# PIC32MM0032GPL020 device description
Architecture: MIPS; Family: PIC32MM1324; Series: PIC32MM
Registers are 32-bit, read-write, no defined reset value unless marked. A register's access mark holds for its fields unless they carry their own. Offsets are from the block's base; [hi:lo] are bit positions; {n}, {i} and the like mark numbered series; 'fields as' and 'values as' point back to an identical list.

## CMP
Instances: CMP 0x1f800900 in periph0
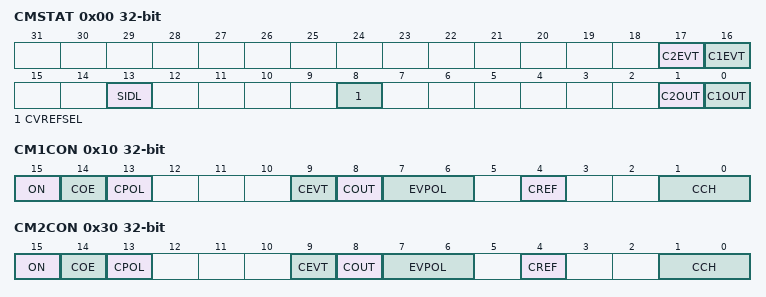
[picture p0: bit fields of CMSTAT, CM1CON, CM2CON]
0x00 CMSTAT
  [17] C2EVT
  [16] C1EVT
  [13] SIDL — Stop in Idle Control bit
    1=All Comparator modules are disabled in Idle mode; 0=All Comparator modules continue to operate in the Idle mode
  [8] CVREFSEL — Comparator Reference Voltage Select (CVREFSEL)
    1=External voltage reference from the CVREF+ pin is selected; 0=Internal band gap voltage reference is selected
  [1] C2OUT — Comparator 2 Output bit
    1=Output of Comparator 2 is a 1; 0=Output of Comparator 2 is a 0
  [0] C1OUT — Comparator 1 Output bit
    1=Output of Comparator 1 is a 1; 0=Output of Comparator 1 is a 0
0x10 CM1CON
  [15] ON — Comparator ON bit
    1=Module is enabled. Setting this bit does not affect the other bits in this register; 0=Module is disabled and does not consume current. Clearing this bit does not affect the other bits in this register
  [14] COE — Comparator Output Enable bit
    1=Comparator output is driven on the output CxOUT pin; 0=Comparator output is not driven on the output CxOUT pin
  [13] CPOL — Comparator Output Inversion bit
    1=Output is inverted; 0=Output is not inverted
  [9] CEVT
  [8] COUT — Comparator Output bit
    1=VIN+ is greater than VIN- (if CPOL = 0)/VIN+ is smaller than VIN- (if CPOL = 1); 0=VIN+ is greater than VIN- (if CPOL = 1)/VIN+ is smaller than VIN- (if CPOL = 0)
  [7:6] EVPOL — Interrupt Event Polarity Select bits
    3=Comparator event is generated on any change of the comparator output; 2=Comparator event is generated on a high-to-low transition (if CPOL = 0) or low-to-high transition (if CPOL = 1) of the comparator output; 1=Comparator event is generated on a high-to-low transition (if CPOL = 1) or low-to-high transition (if CPOL = 0) of the comparator output; 0=Comparator event generation is disabled
  [4] CREF — Comparator Positive Input Configuration
    1=Comparator Non-inverting input connects to the reference defined by the CVREFSEL bit; 0=Comparator non-inverting input is connected to the CxINA pin
  [1:0] CCH — Comparator Negative Input Configuration
    3=Comparator inverting input is connected to the band gap reference voltage; 2=Comparator inverting input is connected to the CxIND pin; 1=Comparator inverting input is connected to the CxINC pin; 0=Comparator inverting input is connected to the CxINB pin
0x30 CM2CON
  fields as CM1CON

## CRC
Instances: CRC 0x1f800a00 in periph0
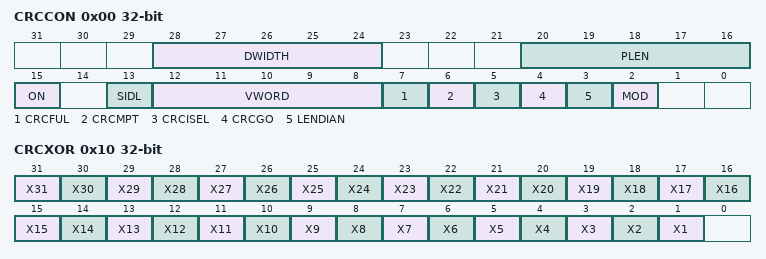
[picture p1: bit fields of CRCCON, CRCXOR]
0x00 CRCCON
  [28:24] DWIDTH, [20:16] PLEN, [15] ON, [13] SIDL, [12:8] VWORD, [7] CRCFUL, [6] CRCMPT, [5] CRCISEL, [4] CRCGO, [3] LENDIAN, [2] MOD
0x10 CRCXOR
  [n] X{n} (n=1..31)
0x20 CRCDAT wo
0x30 CRCWDAT

## GPIO
Instances: GPIO 0x1f802300 in periph0
0x180 RPCON
  [11] IOLOCK
0x1A0 RPINR1
  [4:0] INT4R
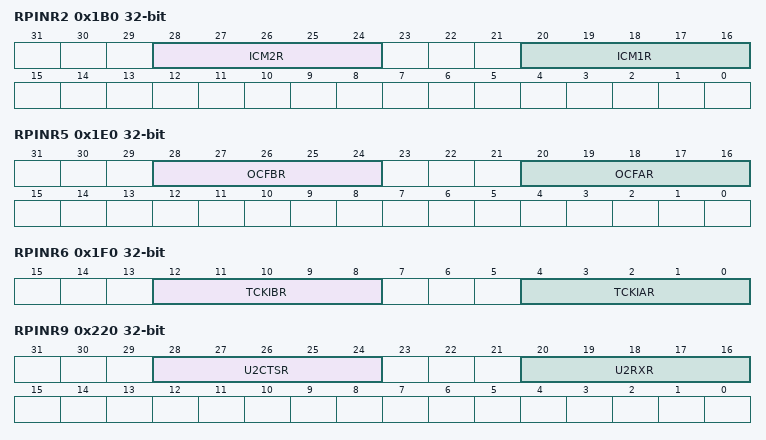
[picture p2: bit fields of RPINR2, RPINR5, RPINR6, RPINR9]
0x1B0 RPINR2
  [28:24] ICM2R, [20:16] ICM1R
0x1C0 RPINR3
  [4:0] ICM3R
0x1E0 RPINR5
  [28:24] OCFBR, [20:16] OCFAR
0x1F0 RPINR6
  [12:8] TCKIBR, [4:0] TCKIAR
0x220 RPINR9
  [28:24] U2CTSR, [20:16] U2RXR
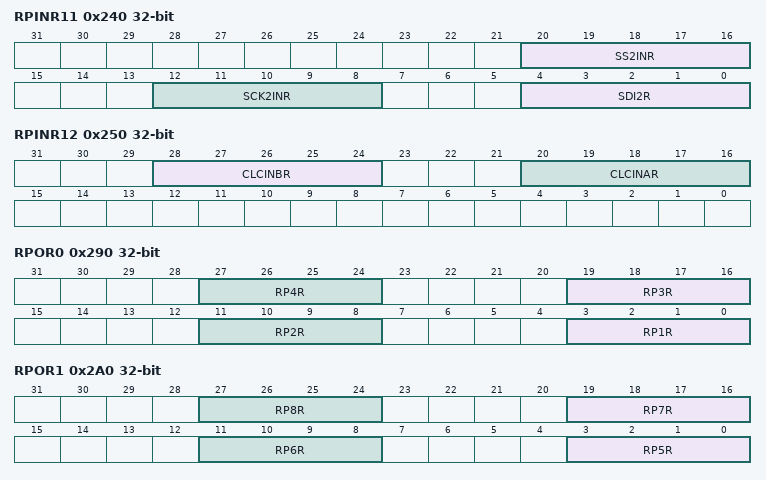
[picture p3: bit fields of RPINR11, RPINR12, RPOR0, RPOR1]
0x240 RPINR11
  [20:16] SS2INR, [12:8] SCK2INR, [4:0] SDI2R
0x250 RPINR12
  [28:24] CLCINBR, [20:16] CLCINAR
0x290 RPOR0
  [8n-5:8n-8] RP{n}R (n=1..4)
0x2A0 RPOR1
  [8n-37:8n-40] RP{n}R (n=5..8)
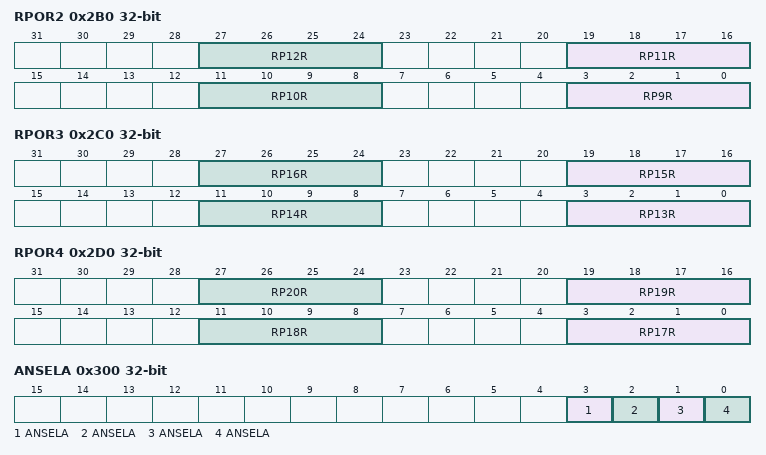
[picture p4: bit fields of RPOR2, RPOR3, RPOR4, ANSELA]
0x2B0 RPOR2
  [8n-69:8n-72] RP{n}R (n=9..12)
0x2C0 RPOR3
  [8n-101:8n-104] RP{n}R (n=13..16)
0x2D0 RPOR4
  [8n-133:8n-136] RP{n}R (n=17..20)
0x300 ANSELA
  [3] ANSELA, [2] ANSELA, [1] ANSELA, [0] ANSELA
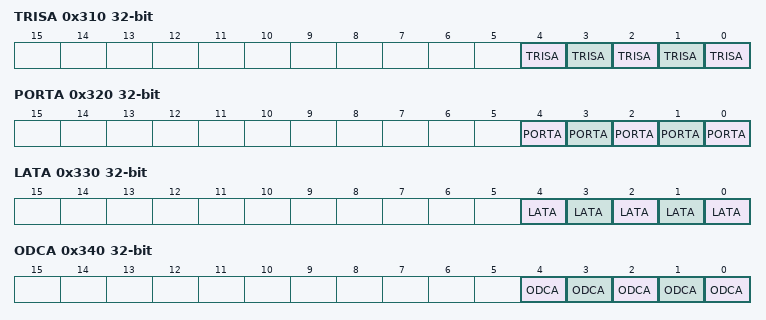
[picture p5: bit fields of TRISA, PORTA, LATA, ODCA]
0x310 TRISA
  [4] TRISA, [3] TRISA, [2] TRISA, [1] TRISA, [0] TRISA
0x320 PORTA
  [4] PORTA, [3] PORTA, [2] PORTA, [1] PORTA, [0] PORTA
0x330 LATA
  [4] LATA, [3] LATA, [2] LATA, [1] LATA, [0] LATA
0x340 ODCA
  [4] ODCA, [3] ODCA, [2] ODCA, [1] ODCA, [0] ODCA
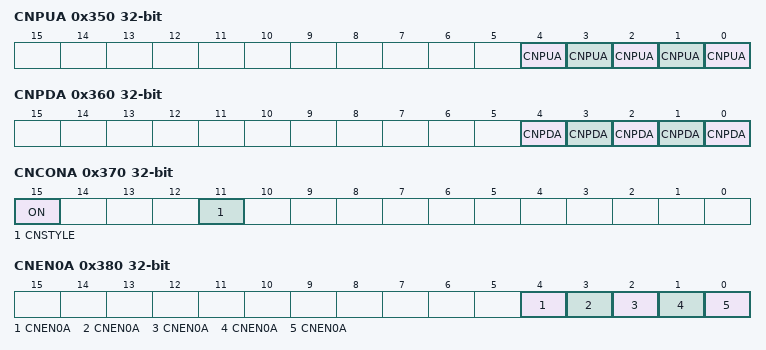
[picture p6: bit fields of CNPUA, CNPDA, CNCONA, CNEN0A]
0x350 CNPUA
  [4] CNPUA, [3] CNPUA, [2] CNPUA, [1] CNPUA, [0] CNPUA
0x360 CNPDA
  [4] CNPDA, [3] CNPDA, [2] CNPDA, [1] CNPDA, [0] CNPDA
0x370 CNCONA
  [15] ON, [11] CNSTYLE
0x380 CNEN0A
  [4] CNEN0A, [3] CNEN0A, [2] CNEN0A, [1] CNEN0A, [0] CNEN0A
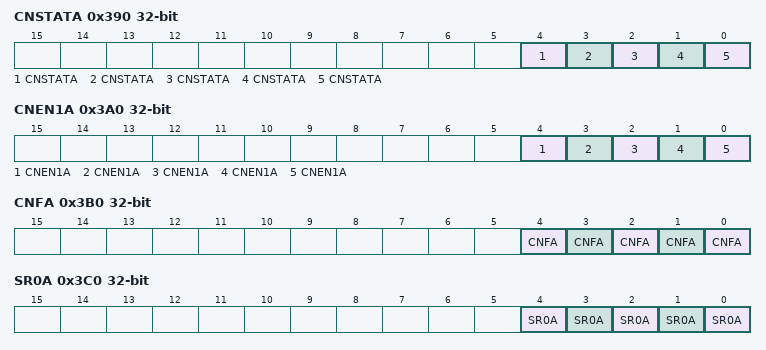
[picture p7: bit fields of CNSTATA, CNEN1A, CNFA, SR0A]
0x390 CNSTATA
  [4] CNSTATA, [3] CNSTATA, [2] CNSTATA, [1] CNSTATA, [0] CNSTATA
0x3A0 CNEN1A
  [4] CNEN1A, [3] CNEN1A, [2] CNEN1A, [1] CNEN1A, [0] CNEN1A
0x3B0 CNFA
  [4] CNFA, [3] CNFA, [2] CNFA, [1] CNFA, [0] CNFA
0x3C0 SR0A
  [4] SR0A, [3] SR0A, [2] SR0A, [1] SR0A, [0] SR0A
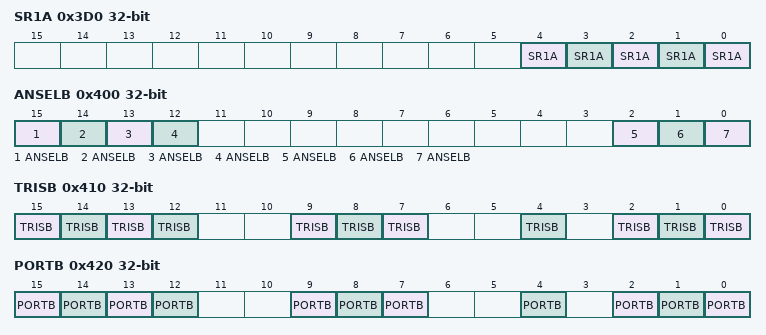
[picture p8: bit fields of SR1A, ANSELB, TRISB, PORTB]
0x3D0 SR1A
  [4] SR1A, [3] SR1A, [2] SR1A, [1] SR1A, [0] SR1A
0x400 ANSELB
  [15] ANSELB, [14] ANSELB, [13] ANSELB, [12] ANSELB, [2] ANSELB, [1] ANSELB, [0] ANSELB
0x410 TRISB
  [15] TRISB, [14] TRISB, [13] TRISB, [12] TRISB, [9] TRISB, [8] TRISB, [7] TRISB, [4] TRISB, [2] TRISB, [1] TRISB, [0] TRISB
0x420 PORTB
  [15] PORTB, [14] PORTB, [13] PORTB, [12] PORTB, [9] PORTB, [8] PORTB, [7] PORTB, [4] PORTB, [2] PORTB, [1] PORTB, [0] PORTB
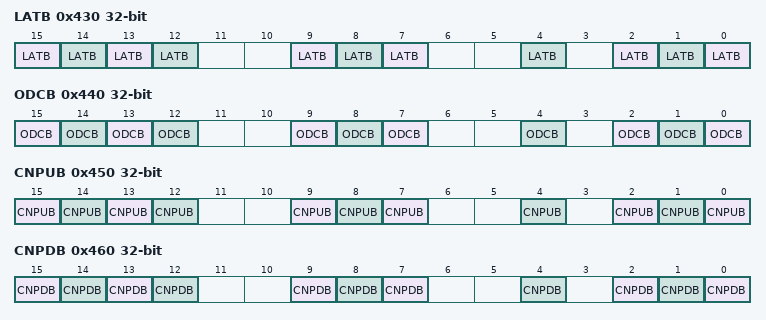
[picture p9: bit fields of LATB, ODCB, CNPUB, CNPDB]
0x430 LATB
  [15] LATB, [14] LATB, [13] LATB, [12] LATB, [9] LATB, [8] LATB, [7] LATB, [4] LATB, [2] LATB, [1] LATB, [0] LATB
0x440 ODCB
  [15] ODCB, [14] ODCB, [13] ODCB, [12] ODCB, [9] ODCB, [8] ODCB, [7] ODCB, [4] ODCB, [2] ODCB, [1] ODCB, [0] ODCB
0x450 CNPUB
  [15] CNPUB, [14] CNPUB, [13] CNPUB, [12] CNPUB, [9] CNPUB, [8] CNPUB, [7] CNPUB, [4] CNPUB, [2] CNPUB, [1] CNPUB, [0] CNPUB
0x460 CNPDB
  [15] CNPDB, [14] CNPDB, [13] CNPDB, [12] CNPDB, [9] CNPDB, [8] CNPDB, [7] CNPDB, [4] CNPDB, [2] CNPDB, [1] CNPDB, [0] CNPDB
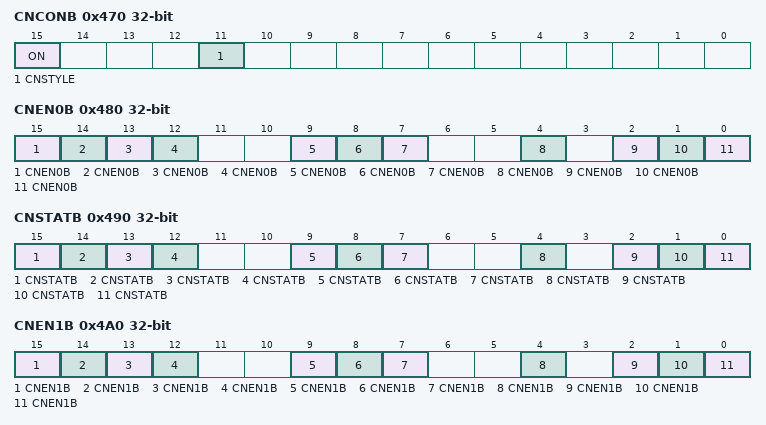
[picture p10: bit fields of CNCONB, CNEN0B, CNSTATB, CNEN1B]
0x470 CNCONB
  [15] ON, [11] CNSTYLE
0x480 CNEN0B
  [15] CNEN0B, [14] CNEN0B, [13] CNEN0B, [12] CNEN0B, [9] CNEN0B, [8] CNEN0B, [7] CNEN0B, [4] CNEN0B, [2] CNEN0B, [1] CNEN0B, [0] CNEN0B
0x490 CNSTATB
  [15] CNSTATB, [14] CNSTATB, [13] CNSTATB, [12] CNSTATB, [9] CNSTATB, [8] CNSTATB, [7] CNSTATB, [4] CNSTATB, [2] CNSTATB, [1] CNSTATB, [0] CNSTATB
0x4A0 CNEN1B
  [15] CNEN1B, [14] CNEN1B, [13] CNEN1B, [12] CNEN1B, [9] CNEN1B, [8] CNEN1B, [7] CNEN1B, [4] CNEN1B, [2] CNEN1B, [1] CNEN1B, [0] CNEN1B
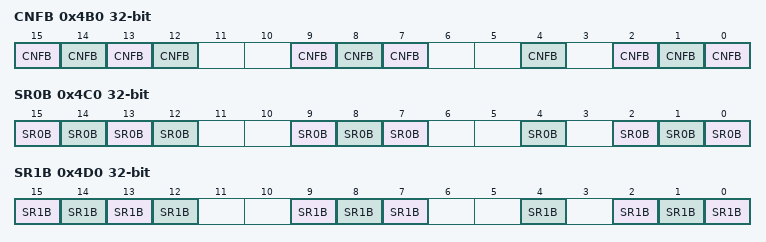
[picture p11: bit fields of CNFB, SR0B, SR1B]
0x4B0 CNFB
  [15] CNFB, [14] CNFB, [13] CNFB, [12] CNFB, [9] CNFB, [8] CNFB, [7] CNFB, [4] CNFB, [2] CNFB, [1] CNFB, [0] CNFB
0x4C0 SR0B
  [15] SR0B, [14] SR0B, [13] SR0B, [12] SR0B, [9] SR0B, [8] SR0B, [7] SR0B, [4] SR0B, [2] SR0B, [1] SR0B, [0] SR0B
0x4D0 SR1B
  [15] SR1B, [14] SR1B, [13] SR1B, [12] SR1B, [9] SR1B, [8] SR1B, [7] SR1B, [4] SR1B, [2] SR1B, [1] SR1B, [0] SR1B

## Notices in the file
Copyright (c) 2019 Microchip Technology Inc.
SPDX-License-Identifier: Apache-2.0
Licensed under the Apache License, Version 2.0 (the "License");
you may not use this file except in compliance with the License.
You may obtain a copy of the License at
http://www.apache.org/licenses/LICENSE-2.0
Unless required by applicable law or agreed to in writing, software
distributed under the License is distributed on an "AS IS" BASIS,
WITHOUT WARRANTIES OR CONDITIONS OF ANY KIND, either express or implied.
See the License for the specific language governing permissions and
limitations under the License.
